# DSS0_VID1 register map
Vendor: Texas Instruments
Peripheral module from a debugger description file (folder J721S2).
Registers are 32-bit, read-write, reset 0x0 unless marked. A register's access mark holds for its fields unless they carry their own. Offsets are as the file gives them; lines under a group give offsets from that group; [hi:lo] are bit positions; {n}, {i} and the like mark numbered series; 'fields as' and 'values as' point back to an identical list; <NAME> marks a mode.

## DSS0_VID1
0x00 DISPC_0_VID1_ACCUH_0 — The register configures the resize accumulator init values for horizontal up/down-sampling of the video window. DISPC_VIDx_ACCU__0 & DISPC_VIDx_ACCU__1 for ping-pong mechanism with external trigger, based on the field polarity. This register is used for ARGB and Y in YUV420/YUV422. Shadow register
  [23:0] HORIZONTALACCU — Horizontal initialization accu signed value
0x04 DISPC_0_VID1_ACCUH_1 — The register configures the resize accumulator init values for horizontal up/down-sampling of the video window. DISPC_VIDx_ACCU__0 & DISPC_VIDx_ACCU__1 for ping-pong mechanism with external trigger, based on the field polarity. This register is used for ARGB and Y in YUV420/YUV422. Shadow register
  [23:0] HORIZONTALACCU — Horizontal initialization accu signed value
0x08 DISPC_0_VID1_ACCUH2_0 — The register configures the resize accumulator init value for horizontal up/down-sampling of the video window. DISPC_VID n_ACCU2__0 & DISPC_VID n_ACCU2__1 for ping-pong mechanism with external trigger, based on the field polarity. This register is used for U/V components in YUV420/YUV422. It is not used when the input format is any RGB format. Shadow register
  [23:0] HORIZONTALACCU — Horizontal initialization accu signed value
0x0C DISPC_0_VID1_ACCUH2_1 — The register configures the resize accumulator init value for horizontal up/down-sampling of the video window. DISPC_VID n_ACCU2__0 & DISPC_VID n_ACCU2__1 for ping-pong mechanism with external trigger, based on the field polarity. This register is used for U/V components in YUV420/YUV422. It is not used when the input format is any RGB format. Shadow register
  [23:0] HORIZONTALACCU — Horizontal initialization accu signed value
0x10 DISPC_0_VID1_ACCUV_0 — The register configures the resize accumulator init values for horizontal and vertical up/down-sampling of the video window. DISPC_VIDx_ACCU__0 & DISPC_VIDx_ACCU__1 for ping-pong mechanism with external trigger, based on the field polarity. It is used for ARGB and Y in YUV420/YUV422. Shadow register
  [23:0] VERTICALACCU — Vertical initialization accu signed value
0x14 DISPC_0_VID1_ACCUV_1 — The register configures the resize accumulator init values for horizontal and vertical up/down-sampling of the video window. DISPC_VIDx_ACCU__0 & DISPC_VIDx_ACCU__1 for ping-pong mechanism with external trigger, based on the field polarity. It is used for ARGB and Y in YUV420/YUV422. Shadow register
  [23:0] VERTICALACCU — Vertical initialization accu signed value
0x18 DISPC_0_VID1_ACCUV2_0 — The register configures the resize accumulator init value for vertical up/down-sampling of the video window. ACCU2__0 & ACCU2__1 for ping-pong mechanism with external trigger, based on the field polarity. It is used for U/V components for YUV420. It is not used when the input format is any RGB format or YUV422. Shadow register
  [23:0] VERTICALACCU — Vertical initialization accu signed value
0x1C DISPC_0_VID1_ACCUV2_1 — The register configures the resize accumulator init value for vertical up/down-sampling of the video window. ACCU2__0 & ACCU2__1 for ping-pong mechanism with external trigger, based on the field polarity. It is used for U/V components for YUV420. It is not used when the input format is any RGB format or YUV422. Shadow register
  [23:0] VERTICALACCU — Vertical initialization accu signed value
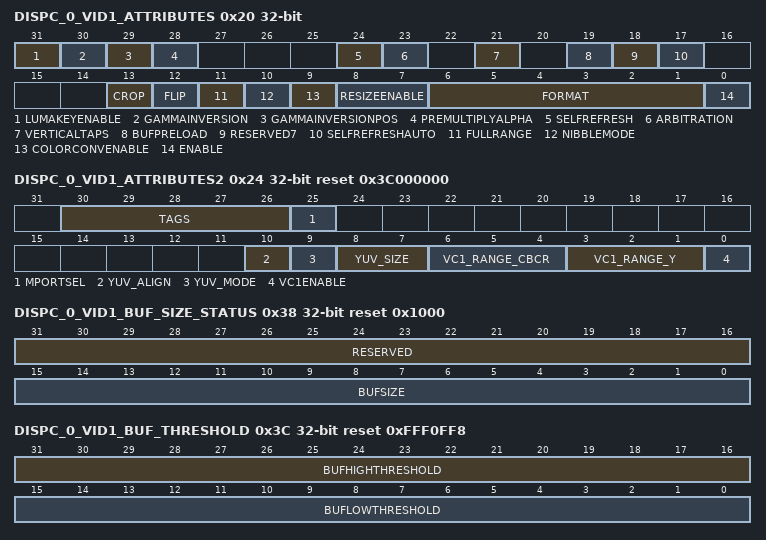
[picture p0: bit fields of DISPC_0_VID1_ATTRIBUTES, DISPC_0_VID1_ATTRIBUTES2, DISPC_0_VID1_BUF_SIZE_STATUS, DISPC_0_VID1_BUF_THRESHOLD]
0x20 DISPC_0_VID1_ATTRIBUTES access per field — The register configures the attributes of the video window. Shadow register
  [31] LUMAKEYENABLE rw — Enable Luma Key transparency matching
  [30] GAMMAINVERSION rw — Inverse Gamma support [using the CLUT table]
  [29] GAMMAINVERSIONPOS rw — Position of Inverse Gamma operation
  [28] PREMULTIPLYALPHA rw — The field configures the DISPC VID to process incoming data as premultiplied alpha data or non premultiplied alpha data. Default setting is non premultiplied alpha data
  [24] SELFREFRESH rw — Enables the self refresh of the video window, from its own DMA buffer only
  [23] ARBITRATION rw — Determines the priority of the video pipeline. The video pipeline is one of the high priority pipelines. The arbitration gives always the priority first to the high priority pipelines using round-robin between them. When there are only normal priority pipelines sending requests, the round-robin applies between the normal priority pipelines
  [21] VERTICALTAPS rw — Video Vertical Resize Tap Number. The vertical poly-phase filter can be configured in 3-tap or 5-tap configuration. According to the number of taps, the maximum input picture width is double while using 3-tap compared to 5-tap
  [19] BUFPRELOAD rw — Video Preload Value
  [18] RESERVED7 ro — Write 0's for future compatibility. Reads return 0
  [17] SELFREFRESHAUTO rw — Automatic self refresh mode
  [13] CROP rw — Enables cropping operation at the output of Video Pipeline
  [12] FLIP rw — Describes the frame buffer flip operation
  [11] FULLRANGE rw — Color Space Conversion full range setting
  [10] NIBBLEMODE rw — Video Nibble mode [only for 1-, 2- and 4-bpp]
  [9] COLORCONVENABLE rw — Enable the color space conversion. The HW does not enable/disable the conversion based on the pixel format
  [8:7] RESIZEENABLE rw — Video Resize Enable
  [6:1] FORMAT rw — Video Format. It defines the pixel format when fetching the video frame buffer
  [0] ENABLE rw — Video pipeline Enable
0x24 DISPC_0_VID1_ATTRIBUTES2 reset 0x3C000000 — The register configures the attributes of the video window. Shadow register
  [30:26] TAGS — Number of OCP TAGS to be used for the pipeline [from 0x0 to 0xF]. A value of 0x0 means only a single tag will be used. A value of 0xF means all 16 tags can be used
  [25] MPORTSEL — Master-Port Selection. By default, use primary master port only
  [10] YUV_ALIGN — Alignment [MSB or LSB align] for unpacked 10b/12b YUV data
  [9] YUV_MODE — Mode of packing for YUV data [only for 10b/12b formats]
  [8:7] YUV_SIZE — Size of YUV data 8b/10b/12b
  [6:4] VC1_RANGE_CBCR — Defines the VC1 range value for the CbCr component from 0 to 7
  [3:1] VC1_RANGE_Y — Defines the VC1 range value for the Y component from 0 to 7
  [0] VC1ENABLE — Enable/disable the VC1 range mapping processing. The bit-field is ignored if the format is not one of the supported YUV formats
0x28 DISPC_0_VID1_BA_0 — The register configures the base address of the single video buffer. In case of single plane ARGB or YUV, this is the BA. In case of two plane YUV, this is the BA_Y. In case of two plane RGB565-A8, this is the BA_Alpha. BA__0 & BA__1 for ping-pong mechanism with external trigger, based on the field polarity otherwise only BA__0 is used. Shadow register
  [31:0] BA — Video base address. Base address of the video buffer [Aligned on pixel size boundary except for the following. In case of RGB24 packed format, 4-pixel alignment is required. In case of YUV422, 2-pixel alignment is required. In case of YUV420, byte alignment is required]
0x2C DISPC_0_VID1_BA_1 — The register configures the base address of the single video buffer. In case of single plane ARGB or YUV, this is the BA. In case of two plane YUV, this is the BA_Y. In case of two plane RGB565-A8, this is the BA_Alpha. BA__0 & BA__1 for ping-pong mechanism with external trigger, based on the field polarity otherwise only BA__0 is used. Shadow register
  fields as DISPC_0_VID1_BA_0
0x30 DISPC_0_VID1_BA_UV_0 — The register configures the base address of the UV buffer for two plane YUV or RGB buffer for two plane RGB565-A8, for the video window. BA_UV__0 & BA_UV__1 for ping-pong mechanism with external trigger, based on the field polarity otherwise only BA_UV__0 is used. Shadow register
  [31:0] BA — Video base address aligned on 16-bit boundary Base address of the UV video buffer used only in case of YUV420-NV12
0x34 DISPC_0_VID1_BA_UV_1 — The register configures the base address of the UV buffer for two plane YUV or RGB buffer for two plane RGB565-A8, for the video window. BA_UV__0 & BA_UV__1 for ping-pong mechanism with external trigger, based on the field polarity otherwise only BA_UV__0 is used. Shadow register
  fields as DISPC_0_VID1_BA_UV_0
0x38 DISPC_0_VID1_BUF_SIZE_STATUS ro reset 0x1000 — The register returns the Video buffer size for the video pipeline
  [31:16] RESERVED — Write 0's for future compatibility Reads return 0
  [15:0] BUFSIZE — Video DMA buffer Size in number of 128-bits
0x3C DISPC_0_VID1_BUF_THRESHOLD reset 0xFFF0FF8 — The register configures the video buffer associated with the video pipeline. Shadow register
  [31:16] BUFHIGHTHRESHOLD — DMA buffer High Threshold. Number of 128-bits defining the threshold value
  [15:0] BUFLOWTHRESHOLD — DMA buffer Low Threshold. Number of 128-bits defining the threshold value
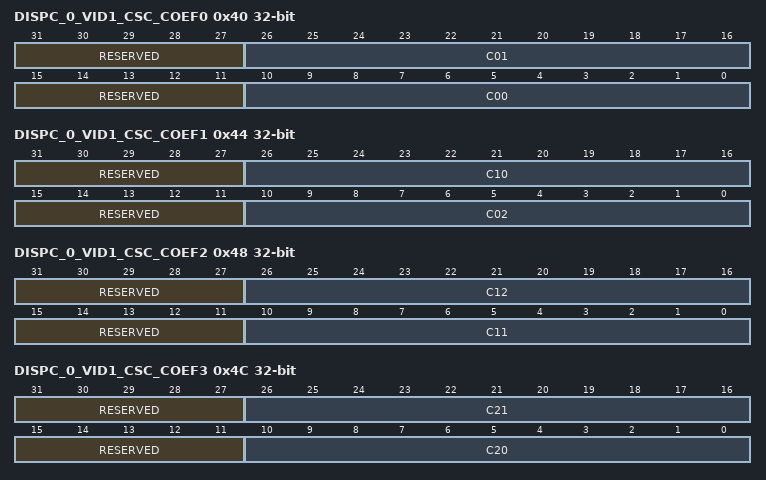
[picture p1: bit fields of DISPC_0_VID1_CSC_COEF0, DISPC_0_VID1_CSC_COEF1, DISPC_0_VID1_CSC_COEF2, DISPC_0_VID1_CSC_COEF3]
0x40 DISPC_0_VID1_CSC_COEF0 access per field — The register configures the color space conversion matrix coefficients. Shadow register
  [31:27] RESERVED ro — Write 0's for future compatibility Reads return 0
  [26:16] C01 rw — C01 Coefficient. Encoded signed value [from -1024 to 1023]
  [15:11] RESERVED ro — Write 0's for future compatibility Reads return 0
  [10:0] C00 rw — C00 Coefficient. Encoded signed value [from -1024 to 1023]
0x44 DISPC_0_VID1_CSC_COEF1 access per field — The register configures the color space conversion matrix coefficients. Shadow register
  [31:27] RESERVED ro — Write 0's for future compatibility Reads return 0
  [26:16] C10 rw — C10 Coefficient. Encoded signed value [from -1024 to 1023]
  [15:11] RESERVED ro — Write 0's for future compatibility Reads return 0
  [10:0] C02 rw — C02 Coefficient. Encoded signed value [from -1024 to 1023]
0x48 DISPC_0_VID1_CSC_COEF2 access per field — The register configures the color space conversion matrix coefficients. Shadow register
  [31:27] RESERVED ro — Write 0's for future compatibility Reads return 0
  [26:16] C12 rw — C12 Coefficient. Encoded signed value [from -1024 to 1023]
  [15:11] RESERVED ro — Write 0's for future compatibility Reads return 0
  [10:0] C11 rw — C11 Coefficient. Encoded signed value [from -1024 to 1023]
0x4C DISPC_0_VID1_CSC_COEF3 access per field — The register configures the color space conversion matrix coefficients. Shadow register
  [31:27] RESERVED ro — Write 0's for future compatibility Reads return 0
  [26:16] C21 rw — C21 coefficient. Encoded signed value [from -1024 to 1023]
  [15:11] RESERVED ro — Write 0's for future compatibility Reads return 0
  [10:0] C20 rw — C20 coefficient. Encoded signed value [from -1024 to 1023]
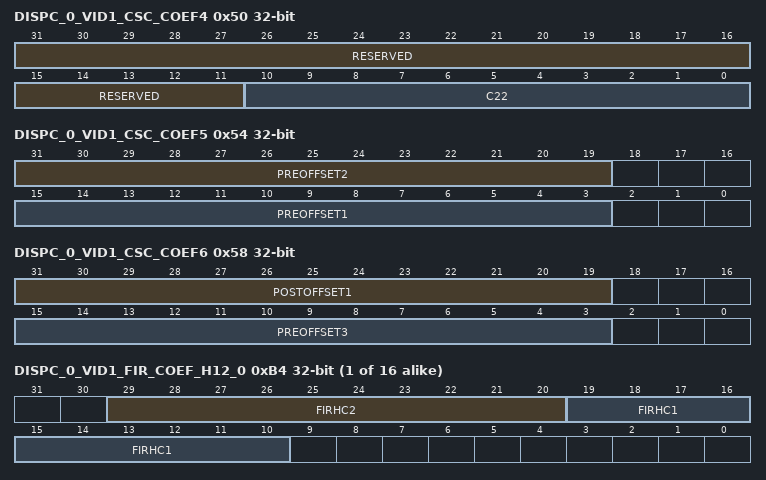
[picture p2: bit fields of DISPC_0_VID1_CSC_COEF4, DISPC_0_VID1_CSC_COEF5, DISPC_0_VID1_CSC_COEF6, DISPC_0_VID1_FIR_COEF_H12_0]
0x50 DISPC_0_VID1_CSC_COEF4 access per field — The register configures the color space conversion matrix coefficients. Shadow register
  [31:11] RESERVED ro — Write 0's for future compatibility Reads return 0
  [10:0] C22 rw — C22 Coefficient. Encoded signed value [from -1024 to 1023]
0x54 DISPC_0_VID1_CSC_COEF5 — The register configures the color space conversion matrix coefficients. Shadow register
  [31:19] PREOFFSET2 — Row-2 pre-offset. Encoded signed value [from -4096 to 4095]
  [15:3] PREOFFSET1 — Row1 pre-offset. Encoded signed value [from -4096 to 4095]
0x58 DISPC_0_VID1_CSC_COEF6 — The register configures the color space conversion matrix coefficients. Shadow register
  [31:19] POSTOFFSET1 — Row-1 post-offset. Encoded signed value [from -4096 to 4095]
  [15:3] PREOFFSET3 — Row-3 pre-offset. Encoded signed value [from -4096 to 4095]
0x5C DISPC_0_VID1_FIRH reset 0x200000 — The register configures the resize factor for horizontal up/down-sampling of the video window. It is used for ARGB and Y setting. Shadow register
  [23:0] FIRHINC — Horizontal increment of the up/down-sampling filter. The value 0 is invalid
0x60 DISPC_0_VID1_FIRH2 reset 0x200000 — The register configures the resize factor for horizontal up/down-sampling of the video window. It is used for U/V components for YUV 422 and 420 input formats. It is not used if input format is any RGB format. Shadow register
  [23:0] FIRHINC — Horizontal increment of the up/down-sampling filter for Cb and Cr. The value 0 is invalid
0x64 DISPC_0_VID1_FIRV reset 0x200000 — The register configures the resize factor for vertical up/down-sampling of the video window. It is used for ARGB and Y setting. Shadow register
  [23:0] FIRVINC — Vertical increment of the up/down-sampling filter. The value 0 is invalid
0x68 DISPC_0_VID1_FIRV2 reset 0x200000 — The register configures the resize factor for vertical up/down-sampling of the video window. It is used for U/V components for YUV420 input format. It is not used when the input format is any RGB format or YUV422 format. Shadow register.
  [23:0] FIRVINC — Vertical increment of the up/down-sampling filter for Cb and Cr. The value 0 is invalid
{0x6C+4i} DISPC_0_VID1_FIR_COEF_H0_{i} (i=0..8) — The bank of registers configures the up/down-scaling coefficients for the horizontal resize of the video picture associated with the video window for the 16 phases. It is used for ARGB and Y setting. Shadow register
  [9:0] FIRHC0 — Unsigned coefficient C0 for the horizontal up/down-scaling with the phase {i}
{0x90+4i} DISPC_0_VID1_FIR_COEF_H0_C_{i} (i=0..8) — The bank of registers configures the up/down-scaling coefficients for the horizontal resize of the video picture associated with the video window for the phases from 0 to 15. It is used for Crb and Cr setting. It is used only when the pixel format at the input of the filter is one of the YUV formats. When the register is not used by the HW, any value can be used for the bit-fields. Shadow register
  fields as DISPC_0_VID1_FIR_COEF_H0_0
{0xB4+4i} DISPC_0_VID1_FIR_COEF_H12_{i} (i=0..15) — The bank of registers configures the up/down-scaling coefficients for the horizontal resize of the video picture associated with the video window for the 16 phases. It is used for ARGB and Y setting. Shadow register
  [29:20] FIRHC2 — Signed coefficient C2 for the horizontal up/down-scaling with the phase {i}
  [19:10] FIRHC1 — Signed coefficient C1 for the horizontal up/down-scaling with the phase {i}
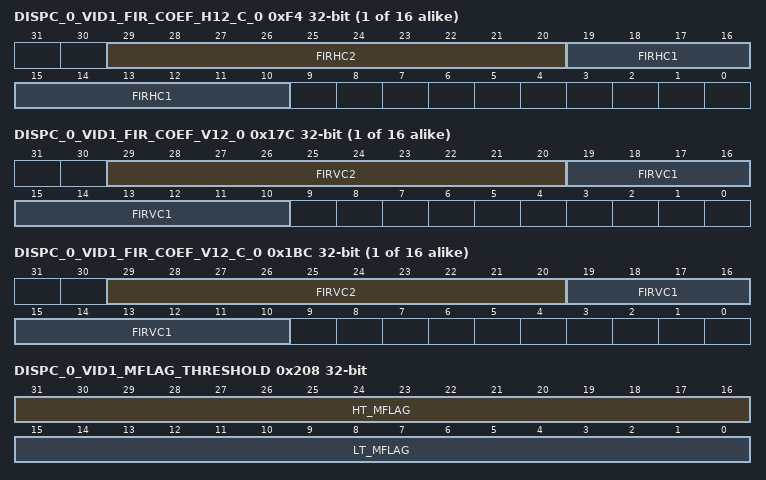
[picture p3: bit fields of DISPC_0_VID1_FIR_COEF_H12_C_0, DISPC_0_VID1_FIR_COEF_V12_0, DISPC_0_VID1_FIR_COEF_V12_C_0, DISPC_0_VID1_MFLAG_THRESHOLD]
{0xF4+4i} DISPC_0_VID1_FIR_COEF_H12_C_{i} (i=0..15) — The bank of registers configures the up/down-scaling coefficients for the horizontal resize of the video picture associated with the video window for the phases from 0 to 15. It is used for Crb and Cr setting. It is used only when the pixel format at the input of the filter is one of the YUV formats. When the register is not used by the HW, any value can be used for the bit-fields. Shadow register
  fields as DISPC_0_VID1_FIR_COEF_H12_0
{0x134+4i} DISPC_0_VID1_FIR_COEF_V0_{i} (i=0..8) — The bank of registers configures the up/down-scaling coefficients for the vertical resize of the video picture associated with the video window for the 16 phases. It is used for ARGB and Y setting. Shadow register
  [9:0] FIRVC0 — Unsigned coefficient C0 for the vertical up/down-scaling with the phase {i}
{0x158+4i} DISPC_0_VID1_FIR_COEF_V0_C_{i} (i=0..8) — The bank of registers configures the up/down-scaling coefficients for the vertical resize of the video picture associated with the video window for the phases from 0 to 15. It is used for Crb and Cr setting. It is used only when the pixel format at the input of the filter is one of the YUV formats. When the register is not used by the HW, any value can be used for the bit-fields. Shadow register
  fields as DISPC_0_VID1_FIR_COEF_V0_0
{0x17C+4i} DISPC_0_VID1_FIR_COEF_V12_{i} (i=0..15) — The bank of registers configures the up/down-scaling coefficients for the vertical resize of the video picture associated with the video window for the 16 phases. It is used for ARGB and Y setting. Shadow register
  [29:20] FIRVC2 — Signed coefficient C2 for the vertical up/down-scaling with the phase {i}
  [19:10] FIRVC1 — Signed coefficient C1 for the vertical up/down-scaling with the phase {i}
{0x1BC+4i} DISPC_0_VID1_FIR_COEF_V12_C_{i} (i=0..15) — The bank of registers configures the up/down-scaling coefficients for the vertical resize of the video picture associated with the video window for the phases from 0 to 15. It is used for Crb and Cr setting. It is used only when the pixel format at the input of the filter is one of the YUV formats. When the register is not used by the HW, any value can be used for the bit-fields. Shadow register
  fields as DISPC_0_VID1_FIR_COEF_V12_0
0x1FC DISPC_0_VID1_GLOBAL_ALPHA reset 0xFF — The register defines the global alpha value for the video pipeline. Shadow register
  [7:0] GLOBALALPHA — Global alpha value from 0 to 255. 0 corresponds to fully transparent and 255 corresponds to fully opaque
0x208 DISPC_0_VID1_MFLAG_THRESHOLD — MFLAG_THRESHOLD Register
  [31:16] HT_MFLAG — MFlag High Threshold
  [15:0] LT_MFLAG — MFlag Low Threshold
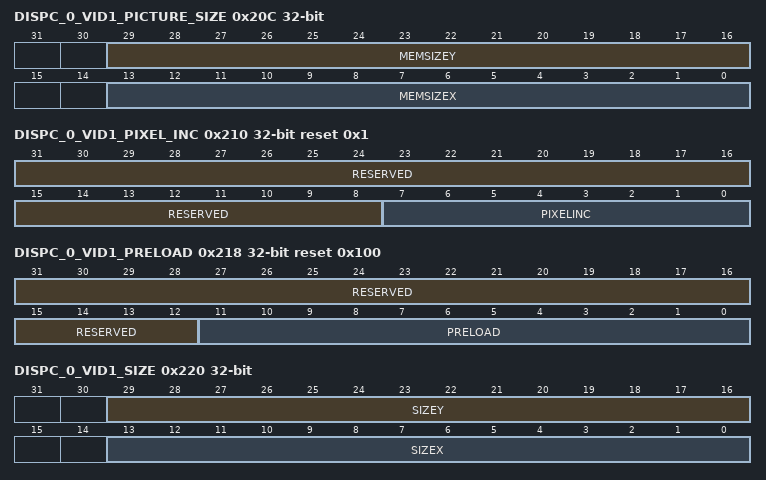
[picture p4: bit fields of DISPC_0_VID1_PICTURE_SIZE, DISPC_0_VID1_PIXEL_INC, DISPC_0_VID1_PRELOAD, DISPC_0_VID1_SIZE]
0x20C DISPC_0_VID1_PICTURE_SIZE — The register configures the size of the video picture associated with the video layer before up/down-scaling. Shadow register
  [29:16] MEMSIZEY — Number of lines of the video picture Encoded value [from 1 to 16384] to specify the number of lines of the video picture in memory [program to value minus one] When predecimation is set, the value represents the size of the image after predecimation but the max size of the unpredecimated image size in memory is still bounded to 2exp[11]
  [13:0] MEMSIZEX — Number of pixels of the video picture Encoded value [from 1 to 16384] to specify the number of pixels of the video picture in memory [program to value minus one]. The size is limited to the size of the line buffer of the vertical sampling block in case the video picture is processed by the vertical filtering unit [program to value minus one]. When predecimation is set, the value represents the size of the image after predecimation but the max size of the unpredecimated image size in memory is still bounded to 2exp[11]
0x210 DISPC_0_VID1_PIXEL_INC access per field reset 0x1 — The register configures the number of bytes to increment between two pixels for the buffer associated with the video window. Shadow register
  [31:8] RESERVED ro — Write 0's for future compatibility Reads return 0
  [7:0] PIXELINC rw — Number of bytes to increment between two pixels Encoded unsigned value [from 1 to 255] to specify the number of bytes between two pixels in the video buffer. The value 0 is invalid The value 1 means next pixel The value 1+n*bpp means increment of n pixels For YUV420. Max supported value is 128
0x218 DISPC_0_VID1_PRELOAD access per field reset 0x100 — The register configures the DMA buffer of the video pipeline. Shadow register
  [31:12] RESERVED ro — Write 0's for future compatibility Reads return 0
  [11:0] PRELOAD rw — DMA buffer preload value Number of 128-bit words defining the preload value
0x21C DISPC_0_VID1_ROW_INC reset 0x1 — The register configures the number of bytes to increment at the end of the row for the buffer associated with the video window. For YUV420 formats this corresponds to the Y Buffer. Shadow register
  [31:0] ROWINC — Number of bytes to increment at the end of the row Encoded signed value [from -2^31-1 to 2^31] to specify the number of bytes to increment at the end of the row in the video buffer. The value 0 is invalid. The value 1 means next pixel. The value 1+n*bpp means increment of n pixels The value 1- [n+1]*bpp means decrement of n pixels
0x220 DISPC_0_VID1_SIZE — The register configures the size of the video window. Shadow register
  [29:16] SIZEY — Number of lines of the video window Encoded value [from 1 to 16384] to specify the number of lines of the video window [program size -1]
  [13:0] SIZEX — Number of pixels of the video window Encoded value [from 1 to 16384] to specify the number of pixels of the video window [program size -1]
0x22C DISPC_0_VID1_BA_EXT_0 — The register configures the 16-bit base address extension. It is the base-address of the single video buffer for single plane ARGB or YUV. For the Y buffer for two plane YUV. For the Alpha buffer for two plane RGB565-A8. 0 & 1 : For ping-pong mechanism with external trigger, based on the field polarity. Shadow register
  [15:0] BA_EXT — Video base address extension [16 bits]. Addr extension to make the address space 48b wide
0x230 DISPC_0_VID1_BA_EXT_1 — The register configures the 16-bit base address extension. It is the base-address of the single video buffer for single plane ARGB or YUV. For the Y buffer for two plane YUV. For the Alpha buffer for two plane RGB565-A8. 0 & 1 : For ping-pong mechanism with external trigger, based on the field polarity. Shadow register
  fields as DISPC_0_VID1_BA_EXT_0
0x234 DISPC_0_VID1_BA_UV_EXT_0 — The register configures the 16-bit base address extension of the UV buffer for two plane YUV or the RGB buffer for two plane RGB565-A8. 0 & 1 : For ping-pong mechanism with external trigger, based on the field polarity. Shadow register
  [15:0] BA_UV_EXT — Video base address extension [16 bits]. Addr extension to make the address space 48b wide
0x238 DISPC_0_VID1_BA_UV_EXT_1 — The register configures the 16-bit base address extension of the UV buffer for two plane YUV or the RGB buffer for two plane RGB565-A8. 0 & 1 : For ping-pong mechanism with external trigger, based on the field polarity. Shadow register
  fields as DISPC_0_VID1_BA_UV_EXT_0
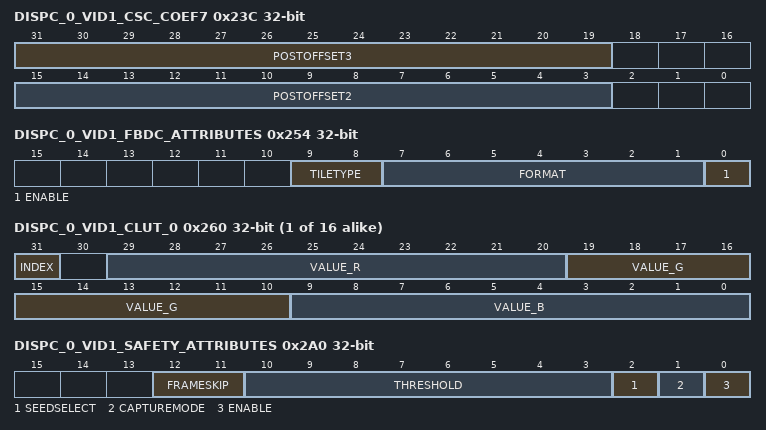
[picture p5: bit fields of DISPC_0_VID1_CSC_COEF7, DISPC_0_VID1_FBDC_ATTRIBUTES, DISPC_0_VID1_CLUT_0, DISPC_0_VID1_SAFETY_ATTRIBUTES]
0x23C DISPC_0_VID1_CSC_COEF7 — The register configures the color space conversion matrix coefficients. Shadow register
  [31:19] POSTOFFSET3 — Row-3 post-offset. Encoded signed value [from -4096 to 4095]
  [15:3] POSTOFFSET2 — Row-2 post-offset. Encoded signed value [from -4096 to 4095]
0x248 DISPC_0_VID1_ROW_INC_UV reset 0x1 — The register configures the number of bytes to increment at the end of the row for the UV buffer associated with the video window for YUV420 formats. For non-YUV420 formats this register is unused. Shadow register
  [31:0] ROWINC — Number of bytes to increment at the end of the row Encoded signed value [from -2^31-1 to 2^31] to specify the number of bytes to increment at the end of the row in the video buffer. The value 0 is invalid The value 1 means next pixel. The value 1+n*bpp means increment of n pixels. The value 1- [n+1]*bpp means decrement of n pixels
0x24C DISPC_0_VID1_TILE — Defines the characteristics of the position of the first pixel inside the compressed frame buffer. In case of non-compressed frame buffer, the register is not used.
  [22:0] TILEINDEX — Defines the tile number for the first tile of the frame buffer: -0 means that the first tile is accessed otherwise some tiles are skipped to support cropping of the frame buffer
0x250 DISPC_0_VID1_TILE2 — Defines the number of tiles in the frame buffer. In case of non-compressed frame buffer, the register is not used.
  [22:0] NUM_TILES — Defines the total number of tiles in the compressed frame buffer
0x254 DISPC_0_VID1_FBDC_ATTRIBUTES — Defines the attributes for the compression engine -FBDC
  [9:8] TILETYPE — FBDC tile-type
  [7:1] FORMAT — FBDC format
  [0] ENABLE — Frame Buffer Compression is Enabled. Transactions shall use secondary master port
0x258 DISPC_0_VID1_FBDC_CLEAR_COLOR — Defines the Clear Color value to be used for the channel in FBDC
  [31:0] CLEARCOLOR
{0x260+4i} DISPC_0_VID1_CLUT_{i} wo (i=0..15) — The register configures the Color Look Up Table CLUT for VID pipeline. CLUT is used in conjunction with bitmap formats
  [31] INDEX — Write 1 to reset the index
  [29:20] VALUE_R — 10-bit R-value to store at the location in the table defined by the incrementing INDEX
  [19:10] VALUE_G — 10-bit G-value to store at the location in the table defined by the incrementing INDEX
  [9:0] VALUE_B — 10-bit B-value to store at the location in the table defined by the incrementing INDEX
0x2A0 DISPC_0_VID1_SAFETY_ATTRIBUTES — The register configures the safety sub-region. Shadow register
  [12:11] FRAMESKIP — Indicates which frames to be skipped while doing FRAMEFREEZE or DATACHECK [Useful for interlaced displays]. 0x0: No frames are skipped, 0x1: Even Frames are skipped starting from second frame after ENABLE, 0x2: Odd Frames are skipped starting from first frame after ENABLE, 0x3: Reserved
  [10:3] THRESHOLD — Allowed maximum number of frames with the same frame signature. When the freeze frame counter reaches 1 over this value [freeze_frame_thold+1], a freeze frame detection will occur. Note: The freeze frame counter is cleared on reset -OR- MISR not enabled -OR- terminal count reached -OR- compare == no match
  [2] SEEDSELECT — Initial seed selection control
  [1] CAPTUREMODE — Mode of operation of the safety check module
  [0] ENABLE — Safety check Enable for the region. Note: Transition from 0 to 1 clears the signature register
0x2A4 DISPC_0_VID1_SAFETY_CAPT_SIGNATURE ro — The register captures the signature from the MISR of the safety sub-region. Shadow register
  [31:0] SIGNATURE — The register configures the reference signature of the safety sub-region. Shadow register
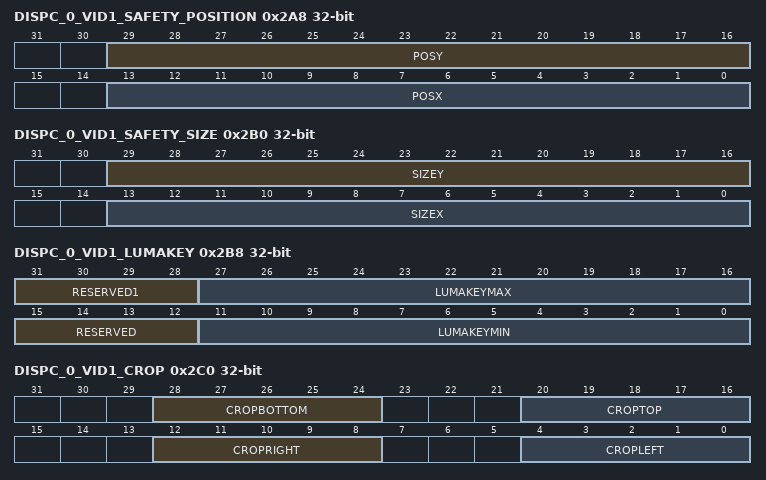
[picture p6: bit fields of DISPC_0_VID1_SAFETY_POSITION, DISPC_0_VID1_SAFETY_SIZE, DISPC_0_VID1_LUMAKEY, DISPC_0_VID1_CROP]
0x2A8 DISPC_0_VID1_SAFETY_POSITION — The register configures the position of the safety sub-region. Shadow register
  [29:16] POSY — Y position of the safety sub-region. Encoded value [from 0 to 16383] to specify the Y position of the sub-region on the screen. The first line on the top of the screen has the Y-position 0
  [13:0] POSX — X position of the safety sub-region. Encoded value [from 0 to 16383] to specify the X position of the sub-region on the screen. The first pixel on the left of the screen has the X-position 0
0x2AC DISPC_0_VID1_SAFETY_REF_SIGNATURE — The register configures the reference signature of the safety sub-region. Shadow register
0x2B0 DISPC_0_VID1_SAFETY_SIZE — The register configures the size of the safety sub-region. Shadow register
  [29:16] SIZEY — Height of the safety sub-region. Encoded value [from 0 to 16383] to specify the height of the sub-region on the screen. One line height region has value of 0
  [13:0] SIZEX — Width of the safety sub-region. Encoded value [from 0 to 16383] to specify the width of the sub-region on the screen. One pixel wide region has value of 0
0x2B4 DISPC_0_VID1_SAFETY_LFSR_SEED — The register configures the seed [initial value] of the MISR. Otherwise, the MISR is initialized with 0xFFFF_FFFF. Shadow register
0x2B8 DISPC_0_VID1_LUMAKEY access per field — The register configures the LUMA KEY transparency min and max values. Shadow register
  [31:28] RESERVED1 ro — Write 0's for future compatibility Reads return 0
  [27:16] LUMAKEYMAX rw — 12b luma_key_max value
  [15:12] RESERVED ro — Write 0's for future compatibility Reads return 0
  [11:0] LUMAKEYMIN rw — 12b luma_key_min value
0x2BC DISPC_0_VID1_DMA_BUFSIZE reset 0x4 — The register configures the DMA buffer size allocated to the pipeline - New Shared memory feature
  [4:0] BUFSIZE — DMA buffer size, if VID pipe is enabled.If the value programmed is n, then the allocated buffer size is 16KB*n. Default:64KB
0x2C0 DISPC_0_VID1_CROP — Defines the attributes for the output cropping in Video Pipe
  [28:24] CROPBOTTOM — Crop Bottom in Lines. Values from 0-31
  [20:16] CROPTOP — Crop Top in Lines. Values from 0-31
  [12:8] CROPRIGHT — Crop Right in Pixels. Values from 0-31
  [4:0] CROPLEFT — Crop Left in Pixels. Values from 0-31
0x2C4 DISPC_0_VID1_SECURE — Security bit settings for the sub-module
  [0] SECURE — Secure bit
0x2C8 DISPC_0_VID1_PIPE_GO — PIPE GO bit settings
  [0] GOBIT
